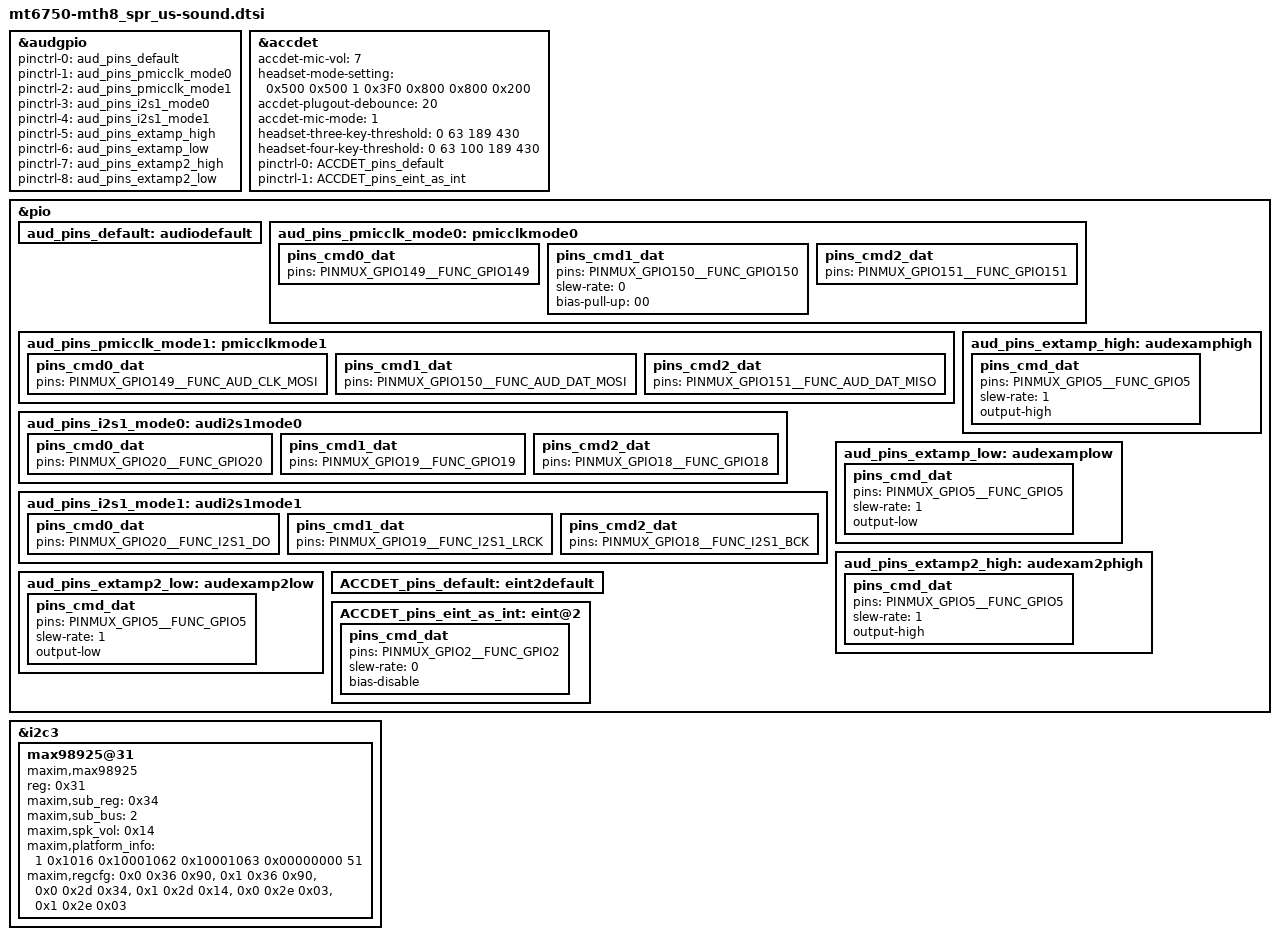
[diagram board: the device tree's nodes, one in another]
/*
 * LG Electronics TH8 sound device tree source
 *
 * Copyright (c) 2017 LG Electronics Co., Ltd.
 *              http://www.lge.com
 *
 */

/* AUDIO GPIO standardization */
&audgpio {
	pinctrl-names = "default", "audpmicclk-mode0", "audpmicclk-mode1",
		"audi2s1-mode0", "audi2s1-mode1", "extamp-pullhigh", "extamp-pulllow",
		"extamp2-pullhigh", "extamp2-pulllow", "rcvspk-pullhigh",
		"rcvspk-pulllow","hpdepop-pullhigh","hpdepop-pulllow";
	pinctrl-0 = <&aud_pins_default>;
	pinctrl-1 = <&aud_pins_pmicclk_mode0>;
	pinctrl-2 = <&aud_pins_pmicclk_mode1>;
	pinctrl-3 = <&aud_pins_i2s1_mode0>;
	pinctrl-4 = <&aud_pins_i2s1_mode1>;
	pinctrl-5 = <&aud_pins_extamp_high>;
	pinctrl-6 = <&aud_pins_extamp_low>;
	pinctrl-7 = <&aud_pins_extamp2_high>;
	pinctrl-8 = <&aud_pins_extamp2_low>;
	/*pinctrl-9 = <&aud_pins_rcvspk_high>;*/
	/*pinctrl-10 = <&aud_pins_rcvspk_low>;*/
	/*pinctrl-11 = <&aud_pins_hpdepop_high>;*/
	/*pinctrl-12 = <&aud_pins_hpdepop_low>;*/
	status = "okay";
};

&accdet {
		accdet-mic-vol = <7>;
		headset-mode-setting = <0x500 0x500 1 0x3F0 0x800 0x800 0x200>;
		accdet-plugout-debounce = <20>;
		/*1:ACC mode, 2:low cost without in bias, 6:low cost with in bias*/
		accdet-mic-mode = <1>;
		/*0--MD_MAX--UP_MAX--DW_MAX*/
		headset-three-key-threshold = <0 63 189 430>;
		/*0--MD_MAX--VOICE_MAX--UP_MAX--DW_MAX*/
		headset-four-key-threshold = <0 63 100 189 430>;
		pinctrl-names = "default", "state_eint_as_int";
		pinctrl-0 = <&ACCDET_pins_default>;
		pinctrl-1 = <&ACCDET_pins_eint_as_int>;
};

&pio {
	aud_pins_default: audiodefault {
	};

	aud_pins_pmicclk_mode0: pmicclkmode0 {
		pins_cmd0_dat {
			pins = <PINMUX_GPIO149__FUNC_GPIO149>;
		};
		pins_cmd1_dat {
			pins = <PINMUX_GPIO150__FUNC_GPIO150>;
			slew-rate = <0>;
			bias-pull-up = <00>;
		};
		pins_cmd2_dat {
			pins = <PINMUX_GPIO151__FUNC_GPIO151>;
		};
	};

	aud_pins_pmicclk_mode1: pmicclkmode1 {
		pins_cmd0_dat {
			pins = <PINMUX_GPIO149__FUNC_AUD_CLK_MOSI>;
		};
		pins_cmd1_dat {
			pins = <PINMUX_GPIO150__FUNC_AUD_DAT_MOSI>;
		};
		pins_cmd2_dat {
			pins = <PINMUX_GPIO151__FUNC_AUD_DAT_MISO>;
		};
	};

	aud_pins_i2s1_mode0: audi2s1mode0 {
		pins_cmd0_dat {
			pins = <PINMUX_GPIO20__FUNC_GPIO20>;
		};
		pins_cmd1_dat {
			pins = <PINMUX_GPIO19__FUNC_GPIO19>;
		};
		pins_cmd2_dat {
			pins = <PINMUX_GPIO18__FUNC_GPIO18>;
		};
	};

	aud_pins_i2s1_mode1: audi2s1mode1 {
		pins_cmd0_dat {
			pins = <PINMUX_GPIO20__FUNC_I2S1_DO>;
		};
		pins_cmd1_dat {
			pins = <PINMUX_GPIO19__FUNC_I2S1_LRCK>;
		};
		pins_cmd2_dat {
			pins = <PINMUX_GPIO18__FUNC_I2S1_BCK>;
		};
	};

	aud_pins_extamp_high: audexamphigh {
		pins_cmd_dat {
			pins = <PINMUX_GPIO5__FUNC_GPIO5>;
			slew-rate = <1>;
			output-high;
		};
	};

	aud_pins_extamp_low: audexamplow {
		pins_cmd_dat {
			pins = <PINMUX_GPIO5__FUNC_GPIO5>;
			slew-rate = <1>;
			output-low;
		};
	};

	aud_pins_extamp2_high: audexam2phigh {
		pins_cmd_dat {
			pins = <PINMUX_GPIO5__FUNC_GPIO5>;
			slew-rate = <1>;
			output-high;
		};
	};
	aud_pins_extamp2_low: audexamp2low {
		pins_cmd_dat {
			pins = <PINMUX_GPIO5__FUNC_GPIO5>;
			slew-rate = <1>;
			output-low;
		};
	};
/*
	aud_pins_rcvspk_high: audrcvspkhigh {
		pins_cmd_dat {
			pins = <PINMUX_GPIO16__FUNC_GPIO16>;
			slew-rate = <1>;
			output-high;
		};
	};

	aud_pins_rcvspk_low: audrcvspklow {
		pins_cmd_dat {
			pins = <PINMUX_GPIO16__FUNC_GPIO16>;
			slew-rate = <1>;
			output-low;
		};
	};

	aud_pins_hpdepop_high: audhpdepophigh {
		pins_cmd_dat {
			pins = <PINMUX_GPIO24__FUNC_GPIO24>;
			slew-rate = <1>;
			output-high;
		};
	};

	aud_pins_hpdepop_low: audhpdepoplow {
		pins_cmd_dat {
			pins = <PINMUX_GPIO24__FUNC_GPIO24>;
			slew-rate = <1>;
			output-low;
		};
	};
*/
	ACCDET_pins_default: eint2default {
	};
	ACCDET_pins_eint_as_int: eint@2 {
		pins_cmd_dat {
			pins = <PINMUX_GPIO2__FUNC_GPIO2>;
			slew-rate = <0>;
			bias-disable;
		};
	};
};


&i2c3 {
	status = "ok";
	max98925@31 {
		status = "ok";
		compatible = "maxim,max98925";
		reg = <0x31>;
		maxim,sub_reg = <0x34>;
		maxim,sub_bus = <2>;
		maxim,spk_vol = <0x14>;
		maxim,platform_info = <1 0x1016 0x10001062 0x10001063 0x00000000 51>;
		maxim,regcfg =
			<0x0 0x36 0x90>,
			<0x1 0x36 0x90>,
			<0x0 0x2d 0x34>,
			<0x1 0x2d 0x14>,
			<0x0 0x2e 0x03>,
			<0x1 0x2e 0x03>;
	};
};
/* AUDIO end */
